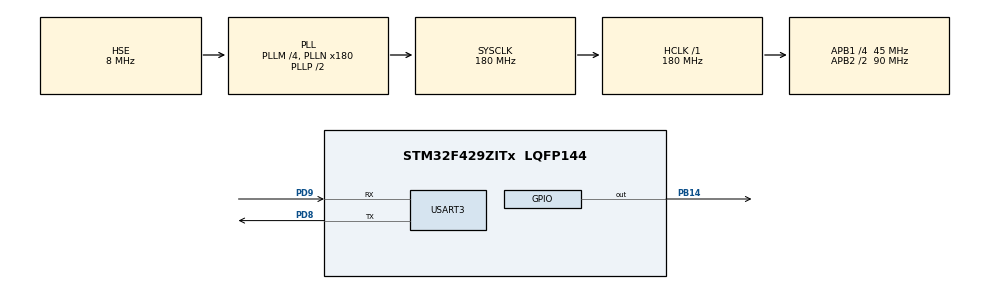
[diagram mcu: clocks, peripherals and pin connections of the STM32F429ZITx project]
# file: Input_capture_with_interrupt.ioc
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Mcu.Family=STM32F4
Mcu.Name=STM32F429ZITx
Mcu.Package=LQFP144
NVIC.PriorityGroup=NVIC_PRIORITYGROUP_4
PA13.Mode=Serial_Wire
PA13.Signal=SYS_JTMS-SWDIO
PA14.Mode=Serial_Wire
PA14.Signal=SYS_JTCK-SWCLK
PB14.Signal=GPIO_Output
PD8.Mode=Asynchronous
PD8.Signal=USART3_TX
PD9.Mode=Asynchronous
PD9.Signal=USART3_RX
PH0/OSC_IN.Mode=HSE-External-Oscillator
PH0/OSC_IN.Signal=RCC_OSC_IN
PH1/OSC_OUT.Mode=HSE-External-Oscillator
PH1/OSC_OUT.Signal=RCC_OSC_OUT
ProjectManager.HeapSize=0x200
ProjectManager.StackSize=0x400
ProjectManager.TargetToolchain=STM32CubeIDE
RCC.48MHZClocksFreq_Value=90000000
RCC.AHBFreq_Value=180000000
RCC.APB1CLKDivider=RCC_HCLK_DIV4
RCC.APB1Freq_Value=45000000
RCC.APB1TimFreq_Value=90000000
RCC.APB2CLKDivider=RCC_HCLK_DIV2
RCC.APB2Freq_Value=90000000
RCC.APB2TimFreq_Value=180000000
RCC.CortexFreq_Value=180000000
RCC.HCLKFreq_Value=180000000
RCC.HSE_VALUE=8000000
RCC.HSI_VALUE=16000000
RCC.LSE_VALUE=32768
RCC.PLLM=4
RCC.PLLN=180
RCC.PLLSourceVirtual=RCC_PLLSOURCE_HSE
RCC.SYSCLKFreq_VALUE=180000000
RCC.SYSCLKSource=RCC_SYSCLKSOURCE_PLLCLK
RCC.VCOOutputFreq_Value=360000000
USART3.VirtualMode=VM_ASYNC
board=custom

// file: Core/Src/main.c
/* USER CODE BEGIN Header */
/**
  ******************************************************************************
  * @file           : main.c
  * @brief          : Main program body
  ******************************************************************************
  * @attention
  *
  * Copyright (c) 2022 STMicroelectronics.
  * All rights reserved.
  *
  * This software is licensed under terms that can be found in the LICENSE file
  * in the root directory of this software component.
  * If no LICENSE file comes with this software, it is provided AS-IS.
  *
  ******************************************************************************
  */
/* USER CODE END Header */
#include "main.h"

/* USER CODE BEGIN Includes */

#include "math.h"
#include "arm_math.h"

#include "input_cap.h"

/* USER CODE END Includes */

/* USER CODE BEGIN PD */
/*

#define TIMCLOCK   90000000
#define PRESCALAR  90
*/

/* USER CODE END PD */

 UART_HandleTypeDef huart3;

/* USER CODE BEGIN PV */

/*

	uint16_t	Last_value = 0;
 	uint16_t	Current_value = 0;
 	uint16_t	period = 0;
 	uint32_t    usWidth = 0;

 	int Is_First_Captured = 0;
 	float refClock;
*/

	float32_t freq = 5.45963f;
	float freq1 = 0.0;
	float32_t freq2 = 0.0;

 	char msg[15] = {0};

	#define FFT_LENGTH  20

 	float fft_outputbuf[FFT_LENGTH];
 	float fft_inputbuf[FFT_LENGTH];

/* USER CODE END PV */

void SystemClock_Config(void);
static void MX_GPIO_Init(void);
static void MX_USART3_UART_Init(void);

int main(void)
{

  /* MCU Configuration--------------------------------------------------------*/

  /* Reset of all peripherals, Initializes the Flash interface and the Systick. */
  HAL_Init();

  /* Configure the system clock */
  SystemClock_Config();

  /* Initialize all configured peripherals */
  MX_GPIO_Init();
  MX_USART3_UART_Init();
  /* USER CODE BEGIN 2 */
  PWM_input_captureInit();
//  PWM_input_capture_interrupt_Init();
//  TIM3_IRQHandler();

  /* USER CODE END 2 */

  /* Infinite loop */
  /* USER CODE BEGIN WHILE */
  while (1)
  {

	  freq1 = arm_sin_f32(frequency);
//	  sprintf(fft_inputbuf,"%f",frequency);
//	  arm_cmplx_mag_f32(fft_inputbuf, fft_outputbuf, FFT_LENGTH);

/*

	 //////////////////////// WORKING ////////////////////////////////
  if(input_start  == 1)
  {
	  input_start = 0;

			while(!(TIM3->SR & 8)){}

			  if (Is_First_Captured == 0)		// if the first value is not captured
			  	  {
			  		  	  Current_value = TIM3->CCR3;		//first value capture
			  		  	  Is_First_Captured = 1;

			  	  }
			  	  else		// if the first is already captured
			  	  {

			  		  	  Last_value = TIM3->CCR3;	//Read last value capture

			  		  	  if(Current_value != 0)
			  				{
			  					period = (Last_value - Current_value);

			  				}

			  			refClock = (TIMCLOCK / TIM3->PSC) ;

			  			frequency = (refClock/period);

			  		  	  Is_First_Captured = 0;

			  	  }
  }

			//////////////////////////////////////////////////////////////////////////
*/

    /* USER CODE END WHILE */

    /* USER CODE BEGIN 3 */

//	  HAL_GPIO_TogglePin(GPIOB, GPIO_PIN_14);
	  //HAL_Delay(500);

  }
  /* USER CODE END 3 */
}

void SystemClock_Config(void)
{
  RCC_OscInitTypeDef RCC_OscInitStruct = {0};
  RCC_ClkInitTypeDef RCC_ClkInitStruct = {0};

  /** Configure the main internal regulator output voltage
  */
  __HAL_RCC_PWR_CLK_ENABLE();
  __HAL_PWR_VOLTAGESCALING_CONFIG(PWR_REGULATOR_VOLTAGE_SCALE1);

  /** Initializes the RCC Oscillators according to the specified parameters
  * in the RCC_OscInitTypeDef structure.
  */
  RCC_OscInitStruct.OscillatorType = RCC_OSCILLATORTYPE_HSE;
  RCC_OscInitStruct.HSEState = RCC_HSE_ON;
  RCC_OscInitStruct.PLL.PLLState = RCC_PLL_ON;
  RCC_OscInitStruct.PLL.PLLSource = RCC_PLLSOURCE_HSE;
  RCC_OscInitStruct.PLL.PLLM = 4;
  RCC_OscInitStruct.PLL.PLLN = 180;
  RCC_OscInitStruct.PLL.PLLP = RCC_PLLP_DIV2;
  RCC_OscInitStruct.PLL.PLLQ = 4;
  if (HAL_RCC_OscConfig(&RCC_OscInitStruct) != HAL_OK)
  {
    Error_Handler();
  }

  /** Activate the Over-Drive mode
  */
  if (HAL_PWREx_EnableOverDrive() != HAL_OK)
  {
    Error_Handler();
  }

  /** Initializes the CPU, AHB and APB buses clocks
  */
  RCC_ClkInitStruct.ClockType = RCC_CLOCKTYPE_HCLK|RCC_CLOCKTYPE_SYSCLK
                              |RCC_CLOCKTYPE_PCLK1|RCC_CLOCKTYPE_PCLK2;
  RCC_ClkInitStruct.SYSCLKSource = RCC_SYSCLKSOURCE_PLLCLK;
  RCC_ClkInitStruct.AHBCLKDivider = RCC_SYSCLK_DIV1;
  RCC_ClkInitStruct.APB1CLKDivider = RCC_HCLK_DIV4;
  RCC_ClkInitStruct.APB2CLKDivider = RCC_HCLK_DIV2;

  if (HAL_RCC_ClockConfig(&RCC_ClkInitStruct, FLASH_LATENCY_5) != HAL_OK)
  {
    Error_Handler();
  }
}

static void MX_USART3_UART_Init(void)
{

  huart3.Instance = USART3;
  huart3.Init.BaudRate = 115200;
  huart3.Init.WordLength = UART_WORDLENGTH_8B;
  huart3.Init.StopBits = UART_STOPBITS_1;
  huart3.Init.Parity = UART_PARITY_NONE;
  huart3.Init.Mode = UART_MODE_TX_RX;
  huart3.Init.HwFlowCtl = UART_HWCONTROL_NONE;
  huart3.Init.OverSampling = UART_OVERSAMPLING_16;
  if (HAL_UART_Init(&huart3) != HAL_OK)
  {
    Error_Handler();
  }

}

static void MX_GPIO_Init(void)
{
  GPIO_InitTypeDef GPIO_InitStruct = {0};

  /* GPIO Ports Clock Enable */
  __HAL_RCC_GPIOH_CLK_ENABLE();
  __HAL_RCC_GPIOB_CLK_ENABLE();
  __HAL_RCC_GPIOD_CLK_ENABLE();
  __HAL_RCC_GPIOA_CLK_ENABLE();

  /*Configure GPIO pin Output Level */
  HAL_GPIO_WritePin(GPIOB, GPIO_PIN_14, GPIO_PIN_RESET);

  /*Configure GPIO pin : PB14 */
  GPIO_InitStruct.Pin = GPIO_PIN_14;
  GPIO_InitStruct.Mode = GPIO_MODE_OUTPUT_PP;
  GPIO_InitStruct.Pull = GPIO_NOPULL;
  GPIO_InitStruct.Speed = GPIO_SPEED_FREQ_LOW;
  HAL_GPIO_Init(GPIOB, &GPIO_InitStruct);

}

/* USER CODE BEGIN 4 */

void UART3_SendChar_RCV (char c)
{
	USART3->DR = c;   // LOad the Data
	while (!(USART3->SR & (1<<6)));  // Wait for TC to SET.. This indicates that the data has been transmitted
}

uint8_t UART3_GetChar (void)
{
		/*********** STEPS FOLLOWED *************

	1. Wait for the RXNE bit to set. It indicates that the data has been received and can be read.
	2. Read the data from USART_DR  Register. This also clears the RXNE bit

	****************************************/
	uint8_t Temp;

	while (!(USART3->SR & (1<<5)));  // Wait for RXNE to SET.. This indicates that the data has been Received
	Temp = USART3->DR;  // Read the data.
	return Temp;
}

					/////////////////////////	STRING SEND  ////////////////////////////

void USART_write(int ch){
while(!(USART3->SR & 0x0080)){
}
USART3->DR=(ch);

}

void UART_Write_String(char *p)
	{
	while(*p!='\0')
{
USART_write(*p);
p++;
}
}
							//////////////////////	END  /////////////////////////

/* USER CODE END 4 */

void Error_Handler(void)
{
  __disable_irq();
  while (1)
  {
  }
}
